# NAVSS0_IO_PVU0_CFG_TLBIF register map
Vendor: Texas Instruments
Peripheral module from a debugger description file (folder J7VCL).
Registers are 32-bit, read-write, reset 0x0 unless marked. A register's access mark holds for its fields unless they carry their own. Offsets are as the file gives them; lines under a group give offsets from that group; [hi:lo] are bit positions; {n}, {i} and the like mark numbered series; 'fields as' and 'values as' point back to an identical list; <NAME> marks a mode.

## NAVSS0_IO_PVU0_CFG_TLBIF
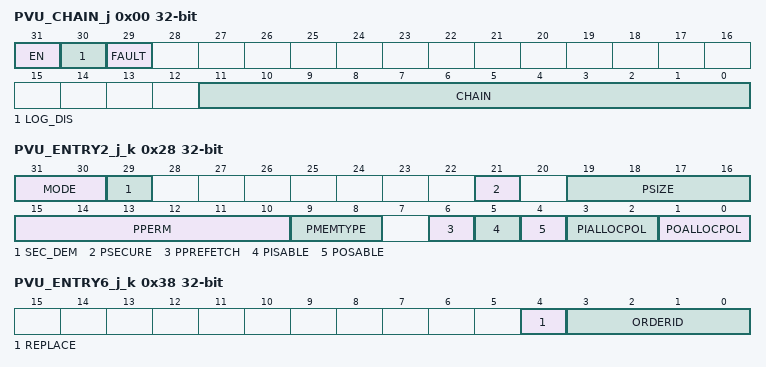
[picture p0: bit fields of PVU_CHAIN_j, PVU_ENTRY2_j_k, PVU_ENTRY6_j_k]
0x00 PVU_CHAIN_j — The TLB chain points to another TLB. The j is the TLB number. Offset = 0h + (j * 1000h); where j = 0h to 3Fh
  [31] EN — Enable for the TLB. 0 = disable TLB. 1 = enable TLB.
  [30] LOG_DIS — Disable Fault Logging for the TLB. 0 = enable fault logging. 1 = disable fault logging.
  [29] FAULT — A fault has been detected from this TLB that could not be logged. Will be set by hardware, and can be cleared by software.
  [11:0] CHAIN — Chain to another TLB. 0 = no chain. &gt;0 = chain to that TLB number.
0x20 PVU_ENTRY0_j_k — The TLB Entry. The j is the TLB number, and the k is the entry number within a TLB. The address must be aligned to the page size. Offset = 20h + (j * 1000h) + (k * 20h); where j = 0h to 3Fh, k = 0h to 7h
  [31:0] VBASE_L — Virtual Base Address bits 31 to 0.The address must be aligned to the page size.
0x24 PVU_ENTRY1_j_k — The TLB Entry. The j is the TLB number, and the k is the entry number within a TLB. The address must be aligned to the page size. Offset = 24h + (j * 1000h) + (k * 20h); where j = 0h to 3Fh, k = 0h to 7h
  [15:0] VBASE_H — Virtual Base Address bits 47 to 32.The address must be aligned to the page size.
0x28 PVU_ENTRY2_j_k — The TLB Entry. The j is the TLB number, and the k is the entry number within a TLB. Offset = 28h + (j * 1000h) + (k * 20h); where j = 0h to 3Fh, k = 0h to 7h
  [31:30] MODE — Entry mode. 0 = invalid. 1 = reserved - do not use. 2 = valid. 3 = reserved - do not use.
  [29] SEC_DEM — Enable Secure Transaction Demotion for the entry if the PVU is in secure mode. 0 = Secure Transactions are not affected. 1 = Secure Transactions that match the entry is demoted to non-secure out of the PVU.
  [21] PSECURE — LPAE Field for Secure Page
  [19:16] PSIZE — LPAE Field for Page Size. 0 = 4K. 1 = 16K. 2 = 64K. 3 = 2M. 4 = 32M. 5 = 512M. 6 = 1G. 7 = 16G.
  [15:10] PPERM — LPAE Field for Page Permissions. Bit 0 = enable user read access UR. Bit 1 = enable user write access UW. Bit 2 = enable user execute access UX. Bit 3 = enable supervisor read access SR. Bit 4 = enable supervisor write access SW. Bit 5 = enable supervisor execute access SX.
  [9:8] PMEMTYPE — LPAE Field for Page Memory Type. 0 = device. 1 = write back. 2 = write through.
  [6] PPREFETCH — LPAE Field for Page Prefetch allowed
  [5] PISABLE — LPAE Field for Page Inner Shareable allowed
  [4] POSABLE — LPAE Field for Page Outer Shareable allowed
  [3:2] PIALLOCPOL — LPAE Field for Page Inner Allocation Policy. 0 = no allocate. 1 = write allocate. 2 = read allocate. 3 = read and write allocate.
  [1:0] POALLOCPOL — LPAE Field for Page Outer Allocation Policy. 0 = no allocate. 1 = write allocate. 2 = read allocate. 3 = read and write allocate.
0x30 PVU_ENTRY4_j_k — The TLB Entry. The j is the TLB number, and the k is the entry number within a TLB. The address must be aligned to the page size. Offset = 30h + (j * 1000h) + (k * 20h); where j = 0h to 3Fh, k = 0h to 7h
  [31:0] PBASE_L — Physical Base Address bits 31 to 0.The address must be aligned to the page size.
0x34 PVU_ENTRY5_j_k — The TLB Entry. The j is the TLB number, and the k is the entry number within a TLB. The address must be aligned to the page size. Offset = 34h + (j * 1000h) + (k * 20h); where j = 0h to 3Fh, k = 0h to 7h
  [15:0] PBASE_H — Physical Base Address bits 47 to 32.The address must be aligned to the page size.
0x38 PVU_ENTRY6_j_k access per field — The TLB Entry. The j is the TLB number, and the k is the entry number within a TLB. Offset = 38h + (j * 1000h) + (k * 20h); where j = 0h to 3Fh, k = 0h to 7h
  [4] REPLACE rw — Indicates to replace the bus orderid value when matching this entry with the ORDERID field. This allows control over the orderid value when it must be restricted due to the topology for QoS reasons. 0 = bypass and use the orderid from the source transaction for the destination transaction. 1 = use the ORDERID field value for the destination transaction.
  [3:0] ORDERID rw — Defines the bus orderid value for this entry if hit.
